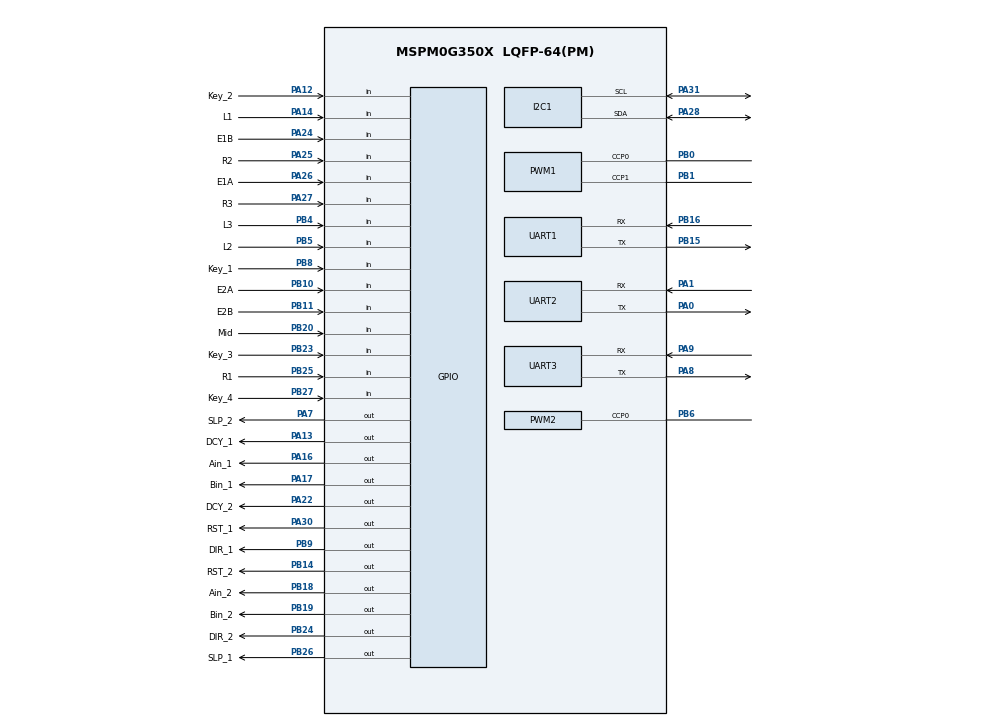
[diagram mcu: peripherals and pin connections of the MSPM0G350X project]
/**
 * @cliArgs --device "MSPM0G350X" --part "Default" --package "LQFP-64(PM)" --product "mspm0_sdk@2.04.00.06"
 * @versions {"tool":"1.23.1+4034"}
 */

/**
 * Import the modules used in this configuration.
 */
const GPIO    = scripting.addModule("/ti/driverlib/GPIO", {}, false);
const GPIO1   = GPIO.addInstance();
const GPIO2   = GPIO.addInstance();
const GPIO3   = GPIO.addInstance();
const GPIO4   = GPIO.addInstance();
const GPIO5   = GPIO.addInstance();
const I2C     = scripting.addModule("/ti/driverlib/I2C", {}, false);
const I2C1    = I2C.addInstance();
const PWM     = scripting.addModule("/ti/driverlib/PWM", {}, false);
const PWM1    = PWM.addInstance();
const PWM2    = PWM.addInstance();
const SYSCTL  = scripting.addModule("/ti/driverlib/SYSCTL");
const SYSTICK = scripting.addModule("/ti/driverlib/SYSTICK");
const TIMER   = scripting.addModule("/ti/driverlib/TIMER", {}, false);
const TIMER1  = TIMER.addInstance();
const UART    = scripting.addModule("/ti/driverlib/UART", {}, false);
const UART1   = UART.addInstance();
const UART2   = UART.addInstance();
const UART3   = UART.addInstance();

/**
 * Write custom configuration values to the imported modules.
 */
const divider6       = system.clockTree["PLL_CLK2X_DIV"];
divider6.divideValue = 4;

const divider7       = system.clockTree["PLL_PDIV"];
divider7.divideValue = 2;

const divider9       = system.clockTree["UDIV"];
divider9.divideValue = 2;

const gate7  = system.clockTree["MFCLKGATE"];
gate7.enable = true;

const multiplier2         = system.clockTree["PLL_QDIV"];
multiplier2.multiplyValue = 10;

const mux4       = system.clockTree["EXHFMUX"];
mux4.inputSelect = "EXHFMUX_XTAL";

const mux8       = system.clockTree["HSCLKMUX"];
mux8.inputSelect = "HSCLKMUX_SYSPLL2X";

const mux10       = system.clockTree["MFPCLKMUX"];
mux10.inputSelect = "MFPCLKMUX_HFCLK";

const pinFunction4     = system.clockTree["HFXT"];
pinFunction4.inputFreq = 40;
pinFunction4.enable    = true;

GPIO1.$name                              = "Key";
GPIO1.associatedPins.create(4);
GPIO1.associatedPins[0].$name            = "Key_2";
GPIO1.associatedPins[0].direction        = "INPUT";
GPIO1.associatedPins[0].internalResistor = "PULL_UP";
GPIO1.associatedPins[0].pin.$assign      = "PA12";
GPIO1.associatedPins[1].direction        = "INPUT";
GPIO1.associatedPins[1].$name            = "Key_1";
GPIO1.associatedPins[1].internalResistor = "PULL_UP";
GPIO1.associatedPins[1].pin.$assign      = "PB8";
GPIO1.associatedPins[2].$name            = "Key_3";
GPIO1.associatedPins[2].direction        = "INPUT";
GPIO1.associatedPins[2].internalResistor = "PULL_UP";
GPIO1.associatedPins[2].pin.$assign      = "PB23";
GPIO1.associatedPins[3].$name            = "Key_4";
GPIO1.associatedPins[3].direction        = "INPUT";
GPIO1.associatedPins[3].internalResistor = "PULL_UP";
GPIO1.associatedPins[3].pin.$assign      = "PB27";

const Board = scripting.addModule("/ti/driverlib/Board", {}, false);

GPIO2.$name                              = "Track_Pin";
GPIO2.associatedPins.create(7);
GPIO2.associatedPins[0].$name            = "L3";
GPIO2.associatedPins[0].direction        = "INPUT";
GPIO2.associatedPins[0].internalResistor = "PULL_UP";
GPIO2.associatedPins[0].pin.$assign      = "PB4";
GPIO2.associatedPins[1].$name            = "L2";
GPIO2.associatedPins[1].direction        = "INPUT";
GPIO2.associatedPins[1].internalResistor = "PULL_UP";
GPIO2.associatedPins[1].pin.$assign      = "PB5";
GPIO2.associatedPins[2].$name            = "L1";
GPIO2.associatedPins[2].internalResistor = "PULL_UP";
GPIO2.associatedPins[2].direction        = "INPUT";
GPIO2.associatedPins[2].pin.$assign      = "PA14";
GPIO2.associatedPins[3].$name            = "Mid";
GPIO2.associatedPins[3].direction        = "INPUT";
GPIO2.associatedPins[3].internalResistor = "PULL_UP";
GPIO2.associatedPins[3].pin.$assign      = "PB20";
GPIO2.associatedPins[4].$name            = "R1";
GPIO2.associatedPins[4].direction        = "INPUT";
GPIO2.associatedPins[4].internalResistor = "PULL_UP";
GPIO2.associatedPins[4].pin.$assign      = "PB25";
GPIO2.associatedPins[5].$name            = "R2";
GPIO2.associatedPins[5].direction        = "INPUT";
GPIO2.associatedPins[5].internalResistor = "PULL_UP";
GPIO2.associatedPins[5].pin.$assign      = "PA25";
GPIO2.associatedPins[6].$name            = "R3";
GPIO2.associatedPins[6].direction        = "INPUT";
GPIO2.associatedPins[6].internalResistor = "PULL_UP";
GPIO2.associatedPins[6].pin.$assign      = "PA27";

GPIO3.$name                         = "Motor";
GPIO3.associatedPins.create(4);
GPIO3.associatedPins[0].$name       = "Ain_2";
GPIO3.associatedPins[0].pin.$assign = "PB18";
GPIO3.associatedPins[1].$name       = "Ain_1";
GPIO3.associatedPins[1].pin.$assign = "PA16";
GPIO3.associatedPins[2].$name       = "Bin_1";
GPIO3.associatedPins[2].pin.$assign = "PA17";
GPIO3.associatedPins[3].$name       = "Bin_2";
GPIO3.associatedPins[3].pin.$assign = "PB19";

GPIO4.$name                               = "Encoder";
GPIO4.associatedPins.create(4);
GPIO4.associatedPins[0].$name             = "E2A";
GPIO4.associatedPins[0].direction         = "INPUT";
GPIO4.associatedPins[0].interruptEn       = true;
GPIO4.associatedPins[0].interruptPriority = "2";
GPIO4.associatedPins[0].polarity          = "RISE";
GPIO4.associatedPins[0].internalResistor  = "PULL_DOWN";
GPIO4.associatedPins[0].pin.$assign       = "PB10";
GPIO4.associatedPins[1].$name             = "E2B";
GPIO4.associatedPins[1].direction         = "INPUT";
GPIO4.associatedPins[1].interruptPriority = "2";
GPIO4.associatedPins[1].internalResistor  = "PULL_DOWN";
GPIO4.associatedPins[1].pin.$assign       = "PB11";
GPIO4.associatedPins[2].$name             = "E1A";
GPIO4.associatedPins[2].direction         = "INPUT";
GPIO4.associatedPins[2].interruptEn       = true;
GPIO4.associatedPins[2].interruptPriority = "2";
GPIO4.associatedPins[2].polarity          = "RISE";
GPIO4.associatedPins[2].internalResistor  = "PULL_DOWN";
GPIO4.associatedPins[2].pin.$assign       = "PA26";
GPIO4.associatedPins[3].$name             = "E1B";
GPIO4.associatedPins[3].direction         = "INPUT";
GPIO4.associatedPins[3].interruptPriority = "2";
GPIO4.associatedPins[3].internalResistor  = "PULL_DOWN";
GPIO4.associatedPins[3].pin.$assign       = "PA24";

GPIO5.$name                         = "Step_Motor";
GPIO5.associatedPins.create(8);
GPIO5.associatedPins[0].$name       = "DIR_1";
GPIO5.associatedPins[0].pin.$assign = "PB9";
GPIO5.associatedPins[1].$name       = "DCY_1";
GPIO5.associatedPins[1].pin.$assign = "PA13";
GPIO5.associatedPins[2].$name       = "SLP_1";
GPIO5.associatedPins[2].pin.$assign = "PB26";
GPIO5.associatedPins[3].$name       = "RST_1";
GPIO5.associatedPins[3].pin.$assign = "PA30";
GPIO5.associatedPins[4].$name       = "DIR_2";
GPIO5.associatedPins[4].pin.$assign = "PB24";
GPIO5.associatedPins[5].$name       = "DCY_2";
GPIO5.associatedPins[5].pin.$assign = "PA22";
GPIO5.associatedPins[6].$name       = "SLP_2";
GPIO5.associatedPins[6].pin.$assign = "PA7";
GPIO5.associatedPins[7].$name       = "RST_2";
GPIO5.associatedPins[7].pin.$assign = "PB14";

I2C1.$name                             = "OLED";
I2C1.advDigitalGlitchFilter            = "CLOCKS_1";
I2C1.advControllerRXFIFOTRIG           = "BYTES_8";
I2C1.advControllerTXFIFOTRIG           = "BYTES_7";
I2C1.enableDMAEvent1                   = false;
I2C1.enableDMAEvent2                   = false;
I2C1.basicEnableController             = true;
I2C1.peripheral.$assign                = "I2C0";
I2C1.peripheral.sdaPin.$assign         = "PA28";
I2C1.peripheral.sclPin.$assign         = "PA31";
I2C1.sdaPinConfig.$name                = "ti_driverlib_gpio_GPIOPinGeneric0";
I2C1.sdaPinConfig.hideOutputInversion  = scripting.forceWrite(false);
I2C1.sdaPinConfig.onlyInternalResistor = scripting.forceWrite(false);
I2C1.sdaPinConfig.passedPeripheralType = scripting.forceWrite("Digital");
I2C1.sdaPinConfig.enableConfig         = true;
I2C1.sdaPinConfig.internalResistor     = "PULL_UP";
I2C1.sclPinConfig.$name                = "ti_driverlib_gpio_GPIOPinGeneric1";
I2C1.sclPinConfig.hideOutputInversion  = scripting.forceWrite(false);
I2C1.sclPinConfig.onlyInternalResistor = scripting.forceWrite(false);
I2C1.sclPinConfig.passedPeripheralType = scripting.forceWrite("Digital");
I2C1.sclPinConfig.enableConfig         = true;
I2C1.sclPinConfig.internalResistor     = "PULL_UP";

PWM1.$name                              = "Motor_Control";
PWM1.pwmMode                            = "EDGE_ALIGN_UP";
PWM1.clockDivider                       = 8;
PWM1.timerStartTimer                    = true;
PWM1.peripheral.$assign                 = "TIMA1";
PWM1.peripheral.ccp0Pin.$assign         = "PB0";
PWM1.peripheral.ccp1Pin.$assign         = "PB1";
PWM1.PWM_CHANNEL_0.$name                = "ti_driverlib_pwm_PWMTimerCC0";
PWM1.PWM_CHANNEL_1.$name                = "ti_driverlib_pwm_PWMTimerCC1";
PWM1.ccp0PinConfig.direction            = scripting.forceWrite("OUTPUT");
PWM1.ccp0PinConfig.hideOutputInversion  = scripting.forceWrite(false);
PWM1.ccp0PinConfig.onlyInternalResistor = scripting.forceWrite(false);
PWM1.ccp0PinConfig.passedPeripheralType = scripting.forceWrite("Digital");
PWM1.ccp0PinConfig.$name                = "ti_driverlib_gpio_GPIOPinGeneric8";
PWM1.ccp1PinConfig.direction            = scripting.forceWrite("OUTPUT");
PWM1.ccp1PinConfig.hideOutputInversion  = scripting.forceWrite(false);
PWM1.ccp1PinConfig.onlyInternalResistor = scripting.forceWrite(false);
PWM1.ccp1PinConfig.passedPeripheralType = scripting.forceWrite("Digital");
PWM1.ccp1PinConfig.$name                = "ti_driverlib_gpio_GPIOPinGeneric9";

PWM2.$name                              = "Step_A";
PWM2.ccIndex                            = [0];
PWM2.clockDivider                       = 8;
PWM2.pwmMode                            = "EDGE_ALIGN_UP";
PWM2.interrupts                         = ["LOAD_EVENT"];
PWM2.PWM_CHANNEL_0.$name                = "ti_driverlib_pwm_PWMTimerCC4";
PWM2.PWM_CHANNEL_0.dutyCycle            = 50;
PWM2.ccp0PinConfig.direction            = scripting.forceWrite("OUTPUT");
PWM2.ccp0PinConfig.hideOutputInversion  = scripting.forceWrite(false);
PWM2.ccp0PinConfig.onlyInternalResistor = scripting.forceWrite(false);
PWM2.ccp0PinConfig.passedPeripheralType = scripting.forceWrite("Digital");
PWM2.ccp0PinConfig.$name                = "ti_driverlib_gpio_GPIOPinGeneric12";
PWM2.peripheral.$assign                 = "TIMG6";
PWM2.peripheral.ccp0Pin.$assign         = "PB6";

SYSCTL.forceDefaultClkConfig = true;
SYSCTL.clockTreeEn           = true;

SYSTICK.periodEnable  = true;
SYSTICK.systickEnable = true;
SYSTICK.period        = 80;

TIMER1.timerMode          = "PERIODIC_UP";
TIMER1.timerClkDiv        = 8;
TIMER1.timerStartTimer    = true;
TIMER1.$name              = "NTB";
TIMER1.timerPeriod        = "6000";
TIMER1.timerClkSrc        = "MFCLK";
TIMER1.peripheral.$assign = "TIMG12";

UART1.$name                            = "k230";
UART1.enabledInterrupts                = ["RX"];
UART1.targetBaudRate                   = 115200;
UART1.interruptPriority                = "2";
UART1.peripheral.$assign               = "UART2";
UART1.peripheral.rxPin.$assign         = "PB16";
UART1.peripheral.txPin.$assign         = "PB15";
UART1.txPinConfig.direction            = scripting.forceWrite("OUTPUT");
UART1.txPinConfig.hideOutputInversion  = scripting.forceWrite(false);
UART1.txPinConfig.onlyInternalResistor = scripting.forceWrite(false);
UART1.txPinConfig.passedPeripheralType = scripting.forceWrite("Digital");
UART1.txPinConfig.$name                = "ti_driverlib_gpio_GPIOPinGeneric4";
UART1.rxPinConfig.hideOutputInversion  = scripting.forceWrite(false);
UART1.rxPinConfig.onlyInternalResistor = scripting.forceWrite(false);
UART1.rxPinConfig.passedPeripheralType = scripting.forceWrite("Digital");
UART1.rxPinConfig.$name                = "ti_driverlib_gpio_GPIOPinGeneric5";

UART2.$name                            = "BLE";
UART2.enabledInterrupts                = ["RX"];
UART2.interruptPriority                = "2";
UART2.peripheral.$assign               = "UART0";
UART2.peripheral.rxPin.$assign         = "PA1";
UART2.peripheral.txPin.$assign         = "PA0";
UART2.txPinConfig.direction            = scripting.forceWrite("OUTPUT");
UART2.txPinConfig.hideOutputInversion  = scripting.forceWrite(false);
UART2.txPinConfig.onlyInternalResistor = scripting.forceWrite(false);
UART2.txPinConfig.passedPeripheralType = scripting.forceWrite("Digital");
UART2.txPinConfig.$name                = "ti_driverlib_gpio_GPIOPinGeneric6";
UART2.rxPinConfig.hideOutputInversion  = scripting.forceWrite(false);
UART2.rxPinConfig.onlyInternalResistor = scripting.forceWrite(false);
UART2.rxPinConfig.passedPeripheralType = scripting.forceWrite("Digital");
UART2.rxPinConfig.$name                = "ti_driverlib_gpio_GPIOPinGeneric7";

UART3.$name                            = "jy61p";
UART3.interruptPriority                = "2";
UART3.targetBaudRate                   = 115200;
UART3.enableFIFO                       = true;
UART3.rxTimeoutValue                   = 1;
UART3.enabledInterrupts                = ["RX_TIMEOUT_ERROR"];
UART3.enabledDMARXTriggers             = "DL_UART_DMA_INTERRUPT_RX";
UART3.peripheral.$assign               = "UART1";
UART3.peripheral.rxPin.$assign         = "PA9";
UART3.peripheral.txPin.$assign         = "PA8";
UART3.txPinConfig.direction            = scripting.forceWrite("OUTPUT");
UART3.txPinConfig.hideOutputInversion  = scripting.forceWrite(false);
UART3.txPinConfig.onlyInternalResistor = scripting.forceWrite(false);
UART3.txPinConfig.passedPeripheralType = scripting.forceWrite("Digital");
UART3.txPinConfig.$name                = "ti_driverlib_gpio_GPIOPinGeneric2";
UART3.rxPinConfig.hideOutputInversion  = scripting.forceWrite(false);
UART3.rxPinConfig.onlyInternalResistor = scripting.forceWrite(false);
UART3.rxPinConfig.passedPeripheralType = scripting.forceWrite("Digital");
UART3.rxPinConfig.$name                = "ti_driverlib_gpio_GPIOPinGeneric3";
UART3.rxPinConfig.enableConfig         = true;
UART3.DMA_CHANNEL_RX.$name             = "DMA_CH0";
UART3.DMA_CHANNEL_RX.addressMode       = "f2b";
UART3.DMA_CHANNEL_RX.srcLength         = "BYTE";
UART3.DMA_CHANNEL_RX.dstLength         = "BYTE";

/**
 * Pinmux solution for unlocked pins/peripherals. This ensures that minor changes to the automatic solver in a future
 * version of the tool will not impact the pinmux you originally saw.  These lines can be completely deleted in order to
 * re-solve from scratch.
 */
pinFunction4.peripheral.$suggestSolution           = "SYSCTL";
pinFunction4.peripheral.hfxInPin.$suggestSolution  = "PA5";
pinFunction4.peripheral.hfxOutPin.$suggestSolution = "PA6";
Board.peripheral.$suggestSolution                  = "DEBUGSS";
Board.peripheral.swclkPin.$suggestSolution         = "PA20";
Board.peripheral.swdioPin.$suggestSolution         = "PA19";
UART3.DMA_CHANNEL_RX.peripheral.$suggestSolution   = "DMA_CH0";
